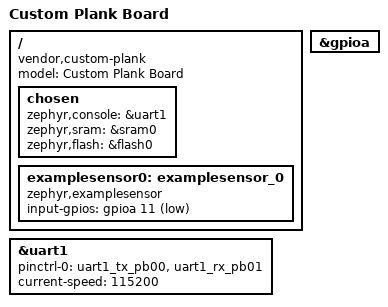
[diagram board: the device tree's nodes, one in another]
/*
 * Copyright (c) 2021 Nordic Semiconductor ASA
 * SPDX-License-Identifier: Apache-2.0
 */

/dts-v1/;
#include <linkedsemi/le501x.dtsi>
#include "custom_plank-pinctrl.dtsi"

/ {
	model = "Custom Plank Board";
	compatible = "vendor,custom-plank";

	chosen {
		zephyr,console = &uart1;
		zephyr,sram = &sram0;
		zephyr,flash = &flash0;
	};

	examplesensor0: examplesensor_0 {
		compatible = "zephyr,examplesensor";
		input-gpios = <&gpioa 11 (GPIO_PULL_UP | GPIO_ACTIVE_LOW)>;
	};
};

&gpioa {
	status = "okay";
};

&uart1 {
	status = "okay";
	pinctrl-0 = <&uart1_tx_pb00 &uart1_rx_pb01>;
	pinctrl-names = "default";
	current-speed = <115200>;
};
